# STM32F3x8 register map
File version: 1.5
CPU: CM4 r1p0, little endian, no MPU, no FPU, 3 interrupt priority bits
Registers are 32-bit, read-write, reset 0x0 unless marked. A register's access mark holds for its fields unless they carry their own. Offsets are from the block's base; [hi:lo] are bit positions; {n}, {i} and the like mark numbered series.

## DAC1 — Digital-to-analog converter
Base 0x40007400
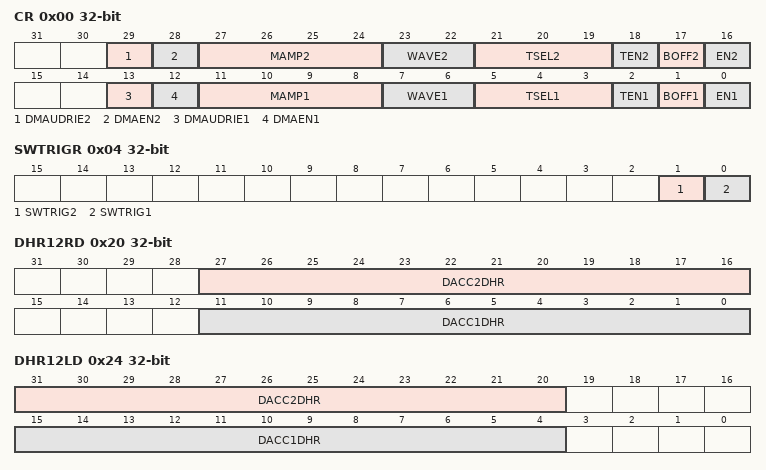
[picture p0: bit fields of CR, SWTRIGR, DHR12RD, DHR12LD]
0x00 CR — control register
  [29] DMAUDRIE2 — DAC channel2 DMA underrun interrupt enable
  [28] DMAEN2 — DAC channel2 DMA enable
  [27:24] MAMP2 — DAC channel2 mask/amplitude selector
  [23:22] WAVE2 — DAC channel2 noise/triangle wave generation enable
  [21:19] TSEL2 — DAC channel2 trigger selection
  [18] TEN2 — DAC channel2 trigger enable
  [17] BOFF2 — DAC channel2 output buffer disable
  [16] EN2 — DAC channel2 enable
  [13] DMAUDRIE1 — DAC channel1 DMA Underrun Interrupt enable
  [12] DMAEN1 — DAC channel1 DMA enable
  [11:8] MAMP1 — DAC channel1 mask/amplitude selector
  [7:6] WAVE1 — DAC channel1 noise/triangle wave generation enable
  [5:3] TSEL1 — DAC channel1 trigger selection
  [2] TEN1 — DAC channel1 trigger enable
  [1] BOFF1 — DAC channel1 output buffer disable
  [0] EN1 — DAC channel1 enable
0x04 SWTRIGR wo — software trigger register
  [1] SWTRIG2 — DAC channel2 software trigger
  [0] SWTRIG1 — DAC channel1 software trigger
0x08 DHR12R1 — channel1 12-bit right-aligned data holding register
  [11:0] DACC1DHR — DAC channel1 12-bit right-aligned data
0x0C DHR12L1 — channel1 12-bit left aligned data holding register
  [15:4] DACC1DHR — DAC channel1 12-bit left-aligned data
0x10 DHR8R1 — channel1 8-bit right aligned data holding register
  [7:0] DACC1DHR — DAC channel1 8-bit right-aligned data
0x14 DHR12R2 — channel2 12-bit right aligned data holding register
  [11:0] DACC2DHR — DAC channel2 12-bit right-aligned data
0x18 DHR12L2 — channel2 12-bit left aligned data holding register
  [15:4] DACC2DHR — DAC channel2 12-bit left-aligned data
0x1C DHR8R2 — channel2 8-bit right-aligned data holding register
  [7:0] DACC2DHR — DAC channel2 8-bit right-aligned data
0x20 DHR12RD — Dual DAC 12-bit right-aligned data holding register
  [27:16] DACC2DHR — DAC channel2 12-bit right-aligned data
  [11:0] DACC1DHR — DAC channel1 12-bit right-aligned data
0x24 DHR12LD — DUAL DAC 12-bit left aligned data holding register
  [31:20] DACC2DHR — DAC channel2 12-bit left-aligned data
  [15:4] DACC1DHR — DAC channel1 12-bit left-aligned data
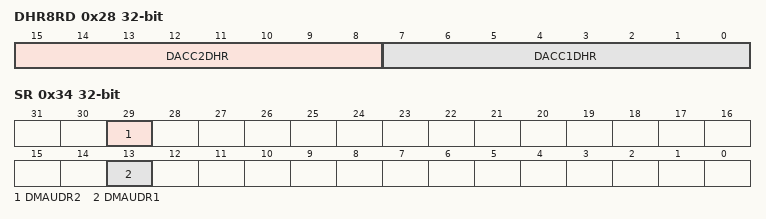
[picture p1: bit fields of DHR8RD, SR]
0x28 DHR8RD — DUAL DAC 8-bit right aligned data holding register
  [15:8] DACC2DHR — DAC channel2 8-bit right-aligned data
  [7:0] DACC1DHR — DAC channel1 8-bit right-aligned data
0x2C DOR1 ro — channel1 data output register
  [11:0] DACC1DOR — DAC channel1 data output
0x30 DOR2 ro — channel2 data output register
  [11:0] DACC2DOR — DAC channel2 data output
0x34 SR — status register
  [29] DMAUDR2 — DAC channel2 DMA underrun flag
  [13] DMAUDR1 — DAC channel1 DMA underrun flag

## DBGMCU — Debug support
Base 0xE0042000
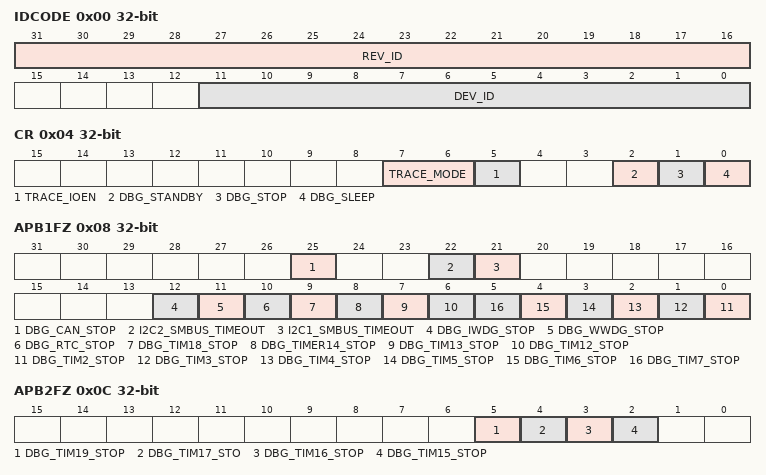
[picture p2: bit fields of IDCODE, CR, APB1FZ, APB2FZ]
0x00 IDCODE ro — MCU Device ID Code Register
  [31:16] REV_ID — Revision Identifier
  [11:0] DEV_ID — Device Identifier
0x04 CR — Debug MCU Configuration Register
  [7:6] TRACE_MODE — Trace pin assignment control
  [5] TRACE_IOEN — Trace pin assignment control
  [2] DBG_STANDBY — Debug Standby Mode
  [1] DBG_STOP — Debug Stop Mode
  [0] DBG_SLEEP — Debug Sleep mode
0x08 APB1FZ — APB Low Freeze Register
  [25] DBG_CAN_STOP — Debug CAN stopped when core is halted
  [22] I2C2_SMBUS_TIMEOUT — SMBUS timeout mode stopped when Core is halted
  [21] I2C1_SMBUS_TIMEOUT — SMBUS timeout mode stopped when Core is halted
  [12] DBG_IWDG_STOP — Debug Independent Wachdog stopped when Core is halted
  [11] DBG_WWDG_STOP — Debug Window Wachdog stopped when Core is halted
  [10] DBG_RTC_STOP — Debug RTC stopped when Core is halted
  [9] DBG_TIM18_STOP — Debug Timer 18 stopped when Core is halted
  [8] DBG_TIMER14_STOP — Debug Timer 14 stopped when Core is halted
  [7] DBG_TIM13_STOP — Debug Timer 13 stopped when Core is halted
  [6] DBG_TIM12_STOP — Debug Timer 12 stopped when Core is halted
  [n-2] DBG_TIM{n}_STOP (n=2..7) — Debug Timer {n} stopped when Core is halted
0x0C APB2FZ — APB High Freeze Register
  [5] DBG_TIM19_STOP — Debug Timer 19 stopped when Core is halted
  [4] DBG_TIM17_STO — Debug Timer 17 stopped when Core is halted
  [3] DBG_TIM16_STOP — Debug Timer 16 stopped when Core is halted
  [2] DBG_TIM15_STOP — Debug Timer 15 stopped when Core is halted
